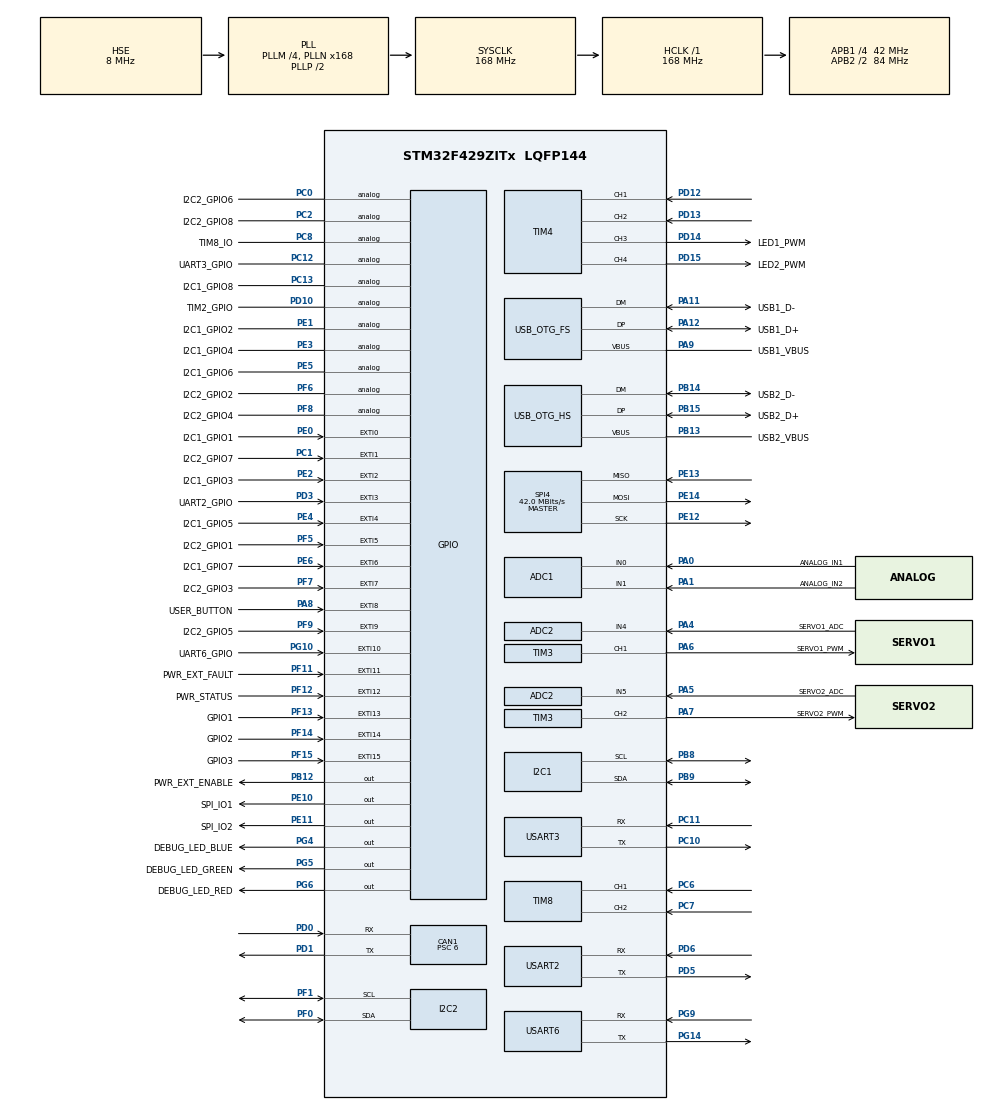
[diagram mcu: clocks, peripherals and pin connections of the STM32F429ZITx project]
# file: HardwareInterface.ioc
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ADC1.Channel-0\#ChannelRegularConversion=ADC_CHANNEL_0
ADC1.ClockPrescaler=ADC_CLOCK_SYNC_PCLK_DIV6
ADC1.NbrOfConversionFlag=1
ADC1.Rank-0\#ChannelRegularConversion=1
ADC1.SamplingTime-0\#ChannelRegularConversion=ADC_SAMPLETIME_3CYCLES
ADC1.master=1
ADC2.Channel-0\#ChannelRegularConversion=ADC_CHANNEL_4
ADC2.ClockPrescaler=ADC_CLOCK_SYNC_PCLK_DIV6
ADC2.NbrOfConversionFlag=1
ADC2.Rank-0\#ChannelRegularConversion=1
ADC2.SamplingTime-0\#ChannelRegularConversion=ADC_SAMPLETIME_3CYCLES
CAN1.BS1=CAN_BS1_11TQ
CAN1.BS2=CAN_BS2_2TQ
CAN1.CalculateBaudRate=500000
CAN1.CalculateTimeBit=2000
CAN1.CalculateTimeQuantum=142.85714285714286
CAN1.NART=ENABLE
CAN1.Prescaler=6
CAN1.SJW=CAN_SJW_4TQ
Dma.ADC1.8.Direction=DMA_PERIPH_TO_MEMORY
Dma.ADC1.8.FIFOMode=DMA_FIFOMODE_DISABLE
Dma.ADC1.8.Instance=DMA2_Stream0
Dma.ADC1.8.MemDataAlignment=DMA_MDATAALIGN_HALFWORD
Dma.ADC1.8.MemInc=DMA_MINC_ENABLE
Dma.ADC1.8.Mode=DMA_NORMAL
Dma.ADC1.8.PeriphDataAlignment=DMA_PDATAALIGN_HALFWORD
Dma.ADC1.8.PeriphInc=DMA_PINC_DISABLE
Dma.ADC1.8.Priority=DMA_PRIORITY_LOW
Dma.ADC2.7.Direction=DMA_PERIPH_TO_MEMORY
Dma.ADC2.7.FIFOMode=DMA_FIFOMODE_DISABLE
Dma.ADC2.7.Instance=DMA2_Stream2
Dma.ADC2.7.MemDataAlignment=DMA_MDATAALIGN_HALFWORD
Dma.ADC2.7.MemInc=DMA_MINC_ENABLE
Dma.ADC2.7.Mode=DMA_NORMAL
Dma.ADC2.7.PeriphDataAlignment=DMA_PDATAALIGN_HALFWORD
Dma.ADC2.7.PeriphInc=DMA_PINC_DISABLE
Dma.ADC2.7.Priority=DMA_PRIORITY_LOW
Dma.MEMTOMEM.9.Direction=DMA_MEMORY_TO_MEMORY
Dma.MEMTOMEM.9.FIFOMode=DMA_FIFOMODE_ENABLE
Dma.MEMTOMEM.9.FIFOThreshold=DMA_FIFO_THRESHOLD_FULL
Dma.MEMTOMEM.9.Instance=DMA2_Stream3
Dma.MEMTOMEM.9.MemBurst=DMA_MBURST_SINGLE
Dma.MEMTOMEM.9.MemDataAlignment=DMA_MDATAALIGN_BYTE
Dma.MEMTOMEM.9.MemInc=DMA_MINC_ENABLE
Dma.MEMTOMEM.9.Mode=DMA_NORMAL
Dma.MEMTOMEM.9.PeriphBurst=DMA_PBURST_SINGLE
Dma.MEMTOMEM.9.PeriphDataAlignment=DMA_PDATAALIGN_BYTE
Dma.MEMTOMEM.9.PeriphInc=DMA_PINC_ENABLE
Dma.MEMTOMEM.9.Priority=DMA_PRIORITY_LOW
Dma.Request0=USART2_RX
Dma.Request1=USART2_TX
Dma.Request2=USART3_RX
Dma.Request3=USART3_TX
Dma.Request4=USART6_RX
Dma.Request5=USART6_TX
Dma.Request6=TIM4_CH3
Dma.Request7=ADC2
Dma.Request8=ADC1
Dma.Request9=MEMTOMEM
Dma.TIM4_CH3.6.Direction=DMA_MEMORY_TO_PERIPH
Dma.TIM4_CH3.6.FIFOMode=DMA_FIFOMODE_DISABLE
Dma.TIM4_CH3.6.Instance=DMA1_Stream7
Dma.TIM4_CH3.6.MemDataAlignment=DMA_MDATAALIGN_HALFWORD
Dma.TIM4_CH3.6.MemInc=DMA_MINC_ENABLE
Dma.TIM4_CH3.6.Mode=DMA_NORMAL
Dma.TIM4_CH3.6.PeriphDataAlignment=DMA_PDATAALIGN_HALFWORD
Dma.TIM4_CH3.6.PeriphInc=DMA_PINC_DISABLE
Dma.TIM4_CH3.6.Priority=DMA_PRIORITY_LOW
Dma.USART2_RX.0.Direction=DMA_PERIPH_TO_MEMORY
Dma.USART2_RX.0.FIFOMode=DMA_FIFOMODE_DISABLE
Dma.USART2_RX.0.Instance=DMA1_Stream5
Dma.USART2_RX.0.MemDataAlignment=DMA_MDATAALIGN_BYTE
Dma.USART2_RX.0.MemInc=DMA_MINC_ENABLE
Dma.USART2_RX.0.Mode=DMA_NORMAL
Dma.USART2_RX.0.PeriphDataAlignment=DMA_PDATAALIGN_BYTE
Dma.USART2_RX.0.PeriphInc=DMA_PINC_DISABLE
Dma.USART2_RX.0.Priority=DMA_PRIORITY_LOW
Dma.USART2_TX.1.Direction=DMA_MEMORY_TO_PERIPH
Dma.USART2_TX.1.FIFOMode=DMA_FIFOMODE_DISABLE
Dma.USART2_TX.1.Instance=DMA1_Stream6
Dma.USART2_TX.1.MemDataAlignment=DMA_MDATAALIGN_BYTE
Dma.USART2_TX.1.MemInc=DMA_MINC_ENABLE
Dma.USART2_TX.1.Mode=DMA_NORMAL
Dma.USART2_TX.1.PeriphDataAlignment=DMA_PDATAALIGN_BYTE
Dma.USART2_TX.1.PeriphInc=DMA_PINC_DISABLE
Dma.USART2_TX.1.Priority=DMA_PRIORITY_LOW
Dma.USART3_RX.2.Direction=DMA_PERIPH_TO_MEMORY
Dma.USART3_RX.2.FIFOMode=DMA_FIFOMODE_DISABLE
Dma.USART3_RX.2.Instance=DMA1_Stream1
Dma.USART3_RX.2.MemDataAlignment=DMA_MDATAALIGN_BYTE
Dma.USART3_RX.2.MemInc=DMA_MINC_ENABLE
Dma.USART3_RX.2.Mode=DMA_NORMAL
Dma.USART3_RX.2.PeriphDataAlignment=DMA_PDATAALIGN_BYTE
Dma.USART3_RX.2.PeriphInc=DMA_PINC_DISABLE
Dma.USART3_RX.2.Priority=DMA_PRIORITY_LOW
Dma.USART3_TX.3.Direction=DMA_MEMORY_TO_PERIPH
Dma.USART3_TX.3.FIFOMode=DMA_FIFOMODE_DISABLE
Dma.USART3_TX.3.Instance=DMA1_Stream3
Dma.USART3_TX.3.MemDataAlignment=DMA_MDATAALIGN_BYTE
Dma.USART3_TX.3.MemInc=DMA_MINC_ENABLE
Dma.USART3_TX.3.Mode=DMA_NORMAL
Dma.USART3_TX.3.PeriphDataAlignment=DMA_PDATAALIGN_BYTE
Dma.USART3_TX.3.PeriphInc=DMA_PINC_DISABLE
Dma.USART3_TX.3.Priority=DMA_PRIORITY_LOW
Dma.USART6_RX.4.Direction=DMA_PERIPH_TO_MEMORY
Dma.USART6_RX.4.FIFOMode=DMA_FIFOMODE_DISABLE
Dma.USART6_RX.4.Instance=DMA2_Stream1
Dma.USART6_RX.4.MemDataAlignment=DMA_MDATAALIGN_BYTE
Dma.USART6_RX.4.MemInc=DMA_MINC_ENABLE
Dma.USART6_RX.4.Mode=DMA_NORMAL
Dma.USART6_RX.4.PeriphDataAlignment=DMA_PDATAALIGN_BYTE
Dma.USART6_RX.4.PeriphInc=DMA_PINC_DISABLE
Dma.USART6_RX.4.Priority=DMA_PRIORITY_LOW
Dma.USART6_TX.5.Direction=DMA_MEMORY_TO_PERIPH
Dma.USART6_TX.5.FIFOMode=DMA_FIFOMODE_DISABLE
Dma.USART6_TX.5.Instance=DMA2_Stream6
Dma.USART6_TX.5.MemDataAlignment=DMA_MDATAALIGN_BYTE
Dma.USART6_TX.5.MemInc=DMA_MINC_ENABLE
Dma.USART6_TX.5.Mode=DMA_NORMAL
Dma.USART6_TX.5.PeriphDataAlignment=DMA_PDATAALIGN_BYTE
Dma.USART6_TX.5.PeriphInc=DMA_PINC_DISABLE
Dma.USART6_TX.5.Priority=DMA_PRIORITY_LOW
FREERTOS.INCLUDE_pcTaskGetTaskName=1
FREERTOS.Tasks01=mainTask,24,4096,StartMainTask,Default,NULL,Static,mainTaskBuffer,mainTaskControlBlock
FREERTOS.configCHECK_FOR_STACK_OVERFLOW=2
FREERTOS.configENABLE_BACKWARD_COMPATIBILITY=1
FREERTOS.configENABLE_FPU=1
FREERTOS.configGENERATE_RUN_TIME_STATS=1
FREERTOS.configMAX_TASK_NAME_LEN=32
FREERTOS.configRECORD_STACK_HIGH_ADDRESS=1
FREERTOS.configTOTAL_HEAP_SIZE=16384
FREERTOS.configUSE_MALLOC_FAILED_HOOK=1
FREERTOS.configUSE_STATS_FORMATTING_FUNCTIONS=1
FREERTOS.copyHeapFile=0
Mcu.Family=STM32F4
Mcu.Name=STM32F429ZITx
Mcu.Package=LQFP144
NVIC.CAN1_RX0_IRQn=true\:5\:0\:false\:false\:true\:true\:true\:true\:true
NVIC.CAN1_RX1_IRQn=true\:5\:0\:false\:false\:true\:true\:true\:true\:true
NVIC.CAN1_SCE_IRQn=true\:5\:0\:false\:false\:true\:true\:true\:true\:true
NVIC.CAN1_TX_IRQn=true\:5\:0\:false\:false\:true\:true\:true\:true\:true
NVIC.DMA1_Stream1_IRQn=true\:5\:0\:false\:false\:true\:true\:false\:true\:true
NVIC.DMA1_Stream3_IRQn=true\:5\:0\:false\:false\:true\:true\:false\:true\:true
NVIC.DMA1_Stream5_IRQn=true\:5\:0\:false\:false\:true\:true\:false\:true\:true
NVIC.DMA1_Stream6_IRQn=true\:5\:0\:false\:false\:true\:true\:false\:true\:true
NVIC.DMA1_Stream7_IRQn=true\:5\:0\:false\:false\:true\:true\:false\:true\:true
NVIC.DMA2_Stream0_IRQn=true\:5\:0\:false\:false\:true\:true\:false\:true\:true
NVIC.DMA2_Stream1_IRQn=true\:5\:0\:false\:false\:true\:true\:false\:true\:true
NVIC.DMA2_Stream2_IRQn=true\:5\:0\:false\:false\:true\:true\:false\:true\:true
NVIC.DMA2_Stream3_IRQn=true\:5\:0\:false\:false\:true\:true\:true\:true\:true
NVIC.DMA2_Stream6_IRQn=true\:5\:0\:false\:false\:true\:true\:false\:true\:true
NVIC.EXTI0_IRQn=true\:5\:0\:false\:false\:true\:true\:true\:true\:true
NVIC.EXTI15_10_IRQn=true\:5\:0\:false\:false\:true\:true\:true\:true\:true
NVIC.EXTI1_IRQn=true\:5\:0\:false\:false\:true\:true\:true\:true\:true
NVIC.EXTI2_IRQn=true\:5\:0\:false\:false\:true\:true\:true\:true\:true
NVIC.EXTI3_IRQn=true\:5\:0\:false\:false\:true\:true\:true\:true\:true
NVIC.EXTI4_IRQn=true\:5\:0\:false\:false\:true\:true\:true\:true\:true
NVIC.EXTI9_5_IRQn=true\:5\:0\:false\:false\:true\:true\:true\:true\:true
NVIC.I2C1_ER_IRQn=true\:5\:0\:false\:false\:true\:true\:true\:true\:true
NVIC.I2C1_EV_IRQn=true\:5\:0\:false\:false\:true\:true\:true\:true\:true
NVIC.I2C2_ER_IRQn=true\:5\:0\:false\:false\:true\:true\:true\:true\:true
NVIC.I2C2_EV_IRQn=true\:5\:0\:false\:false\:true\:true\:true\:true\:true
NVIC.OTG_FS_IRQn=true\:5\:0\:false\:false\:true\:true\:false\:true\:true
NVIC.OTG_HS_EP1_IN_IRQn=true\:5\:0\:false\:false\:true\:true\:false\:true\:true
NVIC.OTG_HS_EP1_OUT_IRQn=true\:5\:0\:false\:false\:true\:true\:false\:true\:true
NVIC.OTG_HS_IRQn=true\:5\:0\:false\:false\:true\:true\:false\:true\:true
NVIC.PriorityGroup=NVIC_PRIORITYGROUP_4
NVIC.TIM7_IRQn=true\:15\:0\:false\:false\:true\:false\:false\:true\:true
NVIC.TIM8_TRG_COM_TIM14_IRQn=true\:5\:0\:false\:false\:true\:false\:false\:true\:true
NVIC.TimeBase=TIM7_IRQn
NVIC.TimeBaseIP=TIM7
NVIC.USART2_IRQn=true\:5\:0\:false\:false\:true\:true\:true\:true\:true
NVIC.USART3_IRQn=true\:5\:0\:false\:false\:true\:true\:true\:true\:true
NVIC.USART6_IRQn=true\:5\:0\:false\:false\:true\:true\:true\:true\:true
PA0/WKUP.GPIO_Label=ANALOG_IN1
PA0/WKUP.Signal=ADCx_IN0
PA1.GPIO_Label=ANALOG_IN2
PA1.Signal=ADCx_IN1
PA11.GPIO_Label=USB1_D-
PA11.Mode=Device_Only
PA11.Signal=USB_OTG_FS_DM
PA12.GPIO_Label=USB1_D+
PA12.Mode=Device_Only
PA12.Signal=USB_OTG_FS_DP
PA13.GPIO_Label=SWD_SWDIO
PA13.Mode=Trace_Asynchronous_SW
PA13.Signal=SYS_JTMS-SWDIO
PA14.GPIO_Label=SWD_SWCLK
PA14.Mode=Trace_Asynchronous_SW
PA14.Signal=SYS_JTCK-SWCLK
PA4.GPIO_Label=SERVO1_ADC
PA4.Signal=ADCx_IN4
PA5.GPIO_Label=SERVO2_ADC
PA5.Signal=ADCx_IN5
PA6.GPIO_Label=SERVO1_PWM
PA6.Signal=S_TIM3_CH1
PA7.GPIO_Label=SERVO2_PWM
PA7.Signal=S_TIM3_CH2
PA8.GPIO_Label=USER_BUTTON
PA8.GPIO_ModeDefaultEXTI=GPIO_MODE_IT_RISING_FALLING
PA8.Signal=GPXTI8
PA9.GPIO_Label=USB1_VBUS
PA9.Mode=Activate_VBUS
PA9.Signal=USB_OTG_FS_VBUS
PB12.GPIO_Label=PWR_EXT_ENABLE
PB12.Signal=GPIO_Output
PB13.GPIO_Label=USB2_VBUS
PB13.Mode=Activate_VBUS_FS
PB13.Signal=USB_OTG_HS_VBUS
PB14.GPIO_Label=USB2_D-
PB14.Mode=Device_Only_FS
PB14.Signal=USB_OTG_HS_DM
PB15.GPIO_Label=USB2_D+
PB15.Mode=Device_Only_FS
PB15.Signal=USB_OTG_HS_DP
PB3.GPIO_Label=SWD_SWO
PB3.Mode=Trace_Asynchronous_SW
PB3.Signal=SYS_JTDO-SWO
PB8.Mode=I2C
PB8.Signal=I2C1_SCL
PB9.Mode=I2C
PB9.Signal=I2C1_SDA
PC0.GPIO_Label=I2C2_GPIO6
PC0.Signal=GPIO_Analog
PC1.GPIO_Label=I2C2_GPIO7
PC1.Signal=GPXTI1
PC10.Mode=Asynchronous
PC10.Signal=USART3_TX
PC11.Mode=Asynchronous
PC11.Signal=USART3_RX
PC12.GPIO_Label=UART3_GPIO
PC12.Signal=GPIO_Analog
PC13.GPIO_Label=I2C1_GPIO8
PC13.Signal=GPIO_Analog
PC2.GPIO_Label=I2C2_GPIO8
PC2.Signal=GPIO_Analog
PC6.Signal=S_TIM8_CH1
PC7.Signal=S_TIM8_CH2
PC8.GPIO_Label=TIM8_IO
PC8.Signal=GPIO_Analog
PD0.Mode=CAN_Activate
PD0.Signal=CAN1_RX
PD1.Mode=CAN_Activate
PD1.Signal=CAN1_TX
PD10.GPIO_Label=TIM2_GPIO
PD10.Signal=GPIO_Analog
PD12.Signal=S_TIM4_CH1
PD13.Signal=S_TIM4_CH2
PD14.GPIO_Label=LED1_PWM
PD14.Signal=S_TIM4_CH3
PD15.GPIO_Label=LED2_PWM
PD15.Signal=S_TIM4_CH4
PD3.GPIO_Label=UART2_GPIO
PD3.Signal=GPXTI3
PD5.Mode=Asynchronous
PD5.Signal=USART2_TX
PD6.Mode=Asynchronous
PD6.Signal=USART2_RX
PE0.GPIO_Label=I2C1_GPIO1
PE0.Signal=GPXTI0
PE1.GPIO_Label=I2C1_GPIO2
PE1.Signal=GPIO_Analog
PE10.GPIO_Label=SPI_IO1
PE10.Signal=GPIO_Output
PE11.GPIO_Label=SPI_IO2
PE11.Signal=GPIO_Output
PE12.Mode=Full_Duplex_Master
PE12.Signal=SPI4_SCK
PE13.Mode=Full_Duplex_Master
PE13.Signal=SPI4_MISO
PE14.Mode=Full_Duplex_Master
PE14.Signal=SPI4_MOSI
PE2.GPIO_Label=I2C1_GPIO3
PE2.Signal=GPXTI2
PE3.GPIO_Label=I2C1_GPIO4
PE3.Signal=GPIO_Analog
PE4.GPIO_Label=I2C1_GPIO5
PE4.Signal=GPXTI4
PE5.GPIO_Label=I2C1_GPIO6
PE5.GPIO_Mode=GPIO_MODE_ANALOG
PE5.Signal=GPIO_Analog
PE6.GPIO_Label=I2C1_GPIO7
PE6.Signal=GPXTI6
PF0.Mode=I2C
PF0.Signal=I2C2_SDA
PF1.Mode=I2C
PF1.Signal=I2C2_SCL
PF11.GPIO_Label=PWR_EXT_FAULT
PF11.Signal=GPXTI11
PF12.GPIO_Label=PWR_STATUS
PF12.Signal=GPXTI12
PF13.GPIO_Label=GPIO1
PF13.Signal=GPXTI13
PF14.GPIO_Label=GPIO2
PF14.Signal=GPXTI14
PF15.GPIO_Label=GPIO3
PF15.Signal=GPXTI15
PF5.GPIO_Label=I2C2_GPIO1
PF5.Signal=GPXTI5
PF6.GPIO_Label=I2C2_GPIO2
PF6.Signal=GPIO_Analog
PF7.GPIO_Label=I2C2_GPIO3
PF7.Signal=GPXTI7
PF8.GPIO_Label=I2C2_GPIO4
PF8.Signal=GPIO_Analog
PF9.GPIO_Label=I2C2_GPIO5
PF9.Signal=GPXTI9
PG10.GPIO_Label=UART6_GPIO
PG10.Signal=GPXTI10
PG14.Mode=Asynchronous
PG14.Signal=USART6_TX
PG4.GPIO_Label=DEBUG_LED_BLUE
PG4.Signal=GPIO_Output
PG5.GPIO_Label=DEBUG_LED_GREEN
PG5.Signal=GPIO_Output
PG6.GPIO_Label=DEBUG_LED_RED
PG6.Signal=GPIO_Output
PG9.Mode=Asynchronous
PG9.Signal=USART6_RX
PH0/OSC_IN.Mode=HSE-External-Clock-Source
PH0/OSC_IN.Signal=RCC_OSC_IN
PH1/OSC_OUT.Mode=HSE-External-Clock-Source
PH1/OSC_OUT.Signal=RCC_OSC_OUT
ProjectManager.HeapSize=0x200
ProjectManager.StackSize=0x400
ProjectManager.TargetToolchain=CMake
RCC.48MHZClocksFreq_Value=48000000
RCC.AHBFreq_Value=168000000
RCC.APB1CLKDivider=RCC_HCLK_DIV4
RCC.APB1Freq_Value=42000000
RCC.APB1TimFreq_Value=84000000
RCC.APB2CLKDivider=RCC_HCLK_DIV2
RCC.APB2Freq_Value=84000000
RCC.APB2TimFreq_Value=168000000
RCC.CortexFreq_Value=168000000
RCC.HCLKFreq_Value=168000000
RCC.HSE_VALUE=8000000
RCC.HSI_VALUE=16000000
RCC.LSE_VALUE=32768
RCC.PLLM=4
RCC.PLLN=168
RCC.PLLQ=7
RCC.SYSCLKFreq_VALUE=168000000
RCC.SYSCLKSource=RCC_SYSCLKSOURCE_PLLCLK
RCC.VCOOutputFreq_Value=336000000
SH.ADCx_IN0.0=ADC1_IN0,IN0
SH.ADCx_IN1.0=ADC1_IN1,IN1
SH.ADCx_IN4.0=ADC2_IN4,IN4
SH.ADCx_IN5.0=ADC2_IN5,IN5
SH.S_TIM3_CH1.0=TIM3_CH1,PWM Generation1 CH1
SH.S_TIM3_CH2.0=TIM3_CH2,PWM Generation2 CH2
SH.S_TIM4_CH1.0=TIM4_CH1,Input_Capture1_from_TI1
SH.S_TIM4_CH2.0=TIM4_CH2,Input_Capture2_from_TI2
SH.S_TIM4_CH3.0=TIM4_CH3,PWM Generation3 CH3
SH.S_TIM4_CH4.0=TIM4_CH4,PWM Generation4 CH4
SH.S_TIM8_CH1.0=TIM8_CH1,Input_Capture1_from_TI1
SH.S_TIM8_CH2.0=TIM8_CH2,Input_Capture2_from_TI2
SPI4.BaudRatePrescaler=SPI_BAUDRATEPRESCALER_2
SPI4.CalculateBaudRate=42.0 MBits/s
SPI4.Direction=SPI_DIRECTION_2LINES
SPI4.Mode=SPI_MODE_MASTER
SPI4.VirtualType=VM_MASTER
TIM3.Channel-PWM\ Generation1\ CH1=TIM_CHANNEL_1
TIM3.Channel-PWM\ Generation2\ CH2=TIM_CHANNEL_2
TIM4.Channel-Input_Capture1_from_TI1=TIM_CHANNEL_1
TIM4.Channel-Input_Capture2_from_TI2=TIM_CHANNEL_2
TIM4.Channel-PWM\ Generation3\ CH3=TIM_CHANNEL_3
TIM4.Channel-PWM\ Generation4\ CH4=TIM_CHANNEL_4
TIM5.Channel-Output\ Compare1\ No\ Output=TIM_CHANNEL_1
TIM8.Channel-Input_Capture1_from_TI1=TIM_CHANNEL_1
TIM8.Channel-Input_Capture2_from_TI2=TIM_CHANNEL_2
USART2.VirtualMode=VM_ASYNC
USART3.VirtualMode=VM_ASYNC
USART6.VirtualMode=VM_ASYNC
USB_DEVICE.CLASS_NAME_FS=CDC
USB_DEVICE.CLASS_NAME_HS=CDC
USB_DEVICE.MANUFACTURER_STRING-CDC_HS=CAuDri e.V.
USB_DEVICE.PID_CDC_FS=22338
USB_DEVICE.PID_CDC_HS=22334
USB_DEVICE.PRODUCT_STRING_CDC_FS=Hardware Interface Host Port
USB_DEVICE.PRODUCT_STRING_CDC_HS=Hardware Interface Debug Port
USB_DEVICE.VirtualMode-CDC_FS=Cdc
USB_DEVICE.VirtualMode-CDC_HS=Cdc
USB_DEVICE.VirtualModeFS=Cdc_FS
USB_DEVICE.VirtualModeHS=Cdc_HS
USB_OTG_FS.Sof_enable=DISABLE
USB_OTG_FS.VirtualMode=Device_Only
USB_OTG_HS.VirtualMode-Device_Only_FS=Device_Only_FS
USB_OTG_HS.use_dedicated_ep1-Device_Only_FS=DISABLE
VP_FREERTOS_VS_CMSIS_V2.Mode=CMSIS_V2
VP_SYS_VS_tim7.Mode=TIM7
VP_TIM5_VS_no_output1.Mode=Output Compare1 No Output
VP_USB_DEVICE_VS_USB_DEVICE_CDC_FS.Mode=CDC_FS
VP_USB_DEVICE_VS_USB_DEVICE_CDC_HS.Mode=CDC_HS
board=custom

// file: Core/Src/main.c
/* USER CODE BEGIN Header */
/**
  ******************************************************************************
  * @file           : main.c
  * @brief          : Main program body
  ******************************************************************************
  * @attention
  *
  * Copyright (c) 2025 STMicroelectronics.
  * All rights reserved.
  *
  * This software is licensed under terms that can be found in the LICENSE file
  * in the root directory of this software component.
  * If no LICENSE file comes with this software, it is provided AS-IS.
  *
  ******************************************************************************
  */
/* USER CODE END Header */
#include "main.h"
#include "cmsis_os.h"
#include "usb_device.h"

/* USER CODE BEGIN Includes */

#include "logger.h"
#include "thread_safe_can.h"
#include "thread_safe_i2c.h"
#include "thread_safe_adc.h"
#include "usb_device_helper.h"
#include "usbd_desc.h"

/* USER CODE END Includes */

typedef StaticTask_t osStaticThreadDef_t;

ADC_HandleTypeDef hadc1;
ADC_HandleTypeDef hadc2;
DMA_HandleTypeDef hdma_adc1;
DMA_HandleTypeDef hdma_adc2;

CAN_HandleTypeDef hcan1;

I2C_HandleTypeDef hi2c1;
I2C_HandleTypeDef hi2c2;

SPI_HandleTypeDef hspi4;

TIM_HandleTypeDef htim3;
TIM_HandleTypeDef htim4;
TIM_HandleTypeDef htim5;
TIM_HandleTypeDef htim8;
DMA_HandleTypeDef hdma_tim4_ch3;

UART_HandleTypeDef huart2;
UART_HandleTypeDef huart3;
UART_HandleTypeDef huart6;
DMA_HandleTypeDef hdma_usart2_rx;
DMA_HandleTypeDef hdma_usart2_tx;
DMA_HandleTypeDef hdma_usart3_rx;
DMA_HandleTypeDef hdma_usart3_tx;
DMA_HandleTypeDef hdma_usart6_rx;
DMA_HandleTypeDef hdma_usart6_tx;

DMA_HandleTypeDef hdma_memtomem_dma2_stream3;
/* Definitions for mainTask */
osThreadId_t mainTaskHandle;
uint32_t mainTaskBuffer[ 4096 ];
osStaticThreadDef_t mainTaskControlBlock;
const osThreadAttr_t mainTask_attributes = {
  .name = "mainTask",
  .cb_mem = &mainTaskControlBlock,
  .cb_size = sizeof(mainTaskControlBlock),
  .stack_mem = &mainTaskBuffer[0],
  .stack_size = sizeof(mainTaskBuffer),
  .priority = (osPriority_t) osPriorityNormal,
};

void SystemClock_Config(void);
static void MX_GPIO_Init(void);
static void MX_DMA_Init(void);
static void MX_ADC1_Init(void);
static void MX_CAN1_Init(void);
static void MX_I2C1_Init(void);
static void MX_I2C2_Init(void);
static void MX_SPI4_Init(void);
static void MX_USART2_UART_Init(void);
static void MX_USART3_UART_Init(void);
static void MX_ADC2_Init(void);
static void MX_TIM3_Init(void);
static void MX_USART6_UART_Init(void);
static void MX_TIM4_Init(void);
static void MX_TIM8_Init(void);
static void MX_TIM5_Init(void);
void StartMainTask(void *argument);

/* USER CODE BEGIN PFP */

// CAuDri - Main entry point in main.cpp
extern void mainTask();

/* USER CODE END PFP */

int main(void)
{

  /* USER CODE BEGIN 1 */

  // CAuDri - Some debug reset paths leave BASEPRI raised, which masks the HAL tick.
  __set_BASEPRI(0U);

  /* USER CODE END 1 */

  /* MCU Configuration--------------------------------------------------------*/

  /* Reset of all peripherals, Initializes the Flash interface and the Systick. */
  HAL_Init();

  /* Configure the system clock */
  SystemClock_Config();

  /* USER CODE BEGIN SysInit */

  // CAuDri - Initialize the trace recorder for debugging with Tracealyzer
  #ifdef DEBUG_USE_TRACE_RECORDER
    xTraceInitialize();
  #endif

  /* USER CODE END SysInit */

  /* Initialize all configured peripherals */
  MX_GPIO_Init();
  MX_DMA_Init();
  MX_ADC1_Init();
  MX_CAN1_Init();
  MX_I2C1_Init();
  MX_I2C2_Init();
  MX_SPI4_Init();
  MX_USART2_UART_Init();
  MX_USART3_UART_Init();
  MX_ADC2_Init();
  MX_TIM3_Init();
  MX_USART6_UART_Init();
  MX_TIM4_Init();
  MX_TIM8_Init();
  MX_TIM5_Init();
  /* USER CODE BEGIN 2 */

  // CAuDri - Replace CubeMX's occasionally broken generated USB serial callback
  usb_serial_descriptor_install(&FS_Desc, &HS_Desc);

  /* USER CODE END 2 */

  /* Init scheduler */
  osKernelInitialize();

  /* Create the thread(s) */
  /* creation of mainTask */
  mainTaskHandle = osThreadNew(StartMainTask, NULL, &mainTask_attributes);

  /* USER CODE BEGIN RTOS_THREADS */

  // CAuDri - Initialize the logging interface and start the logger thread
  if (!logger_init()) {
      LogInline("Main: Failed to initialize logger");
  } else {
      LogClear();
  }

  /* add threads, ... */
  /* USER CODE END RTOS_THREADS */

  /* Start scheduler */
  osKernelStart();

  /* We should never get here as control is now taken by the scheduler */

  /* Infinite loop */
  while (1)
  {

  }
}

void SystemClock_Config(void)
{
  RCC_OscInitTypeDef RCC_OscInitStruct = {0};
  RCC_ClkInitTypeDef RCC_ClkInitStruct = {0};

  /** Configure the main internal regulator output voltage
  */
  __HAL_RCC_PWR_CLK_ENABLE();
  __HAL_PWR_VOLTAGESCALING_CONFIG(PWR_REGULATOR_VOLTAGE_SCALE1);

  /** Initializes the RCC Oscillators according to the specified parameters
  * in the RCC_OscInitTypeDef structure.
  */
  RCC_OscInitStruct.OscillatorType = RCC_OSCILLATORTYPE_HSE;
  RCC_OscInitStruct.HSEState = RCC_HSE_BYPASS;
  RCC_OscInitStruct.PLL.PLLState = RCC_PLL_ON;
  RCC_OscInitStruct.PLL.PLLSource = RCC_PLLSOURCE_HSE;
  RCC_OscInitStruct.PLL.PLLM = 4;
  RCC_OscInitStruct.PLL.PLLN = 168;
  RCC_OscInitStruct.PLL.PLLP = RCC_PLLP_DIV2;
  RCC_OscInitStruct.PLL.PLLQ = 7;
  if (HAL_RCC_OscConfig(&RCC_OscInitStruct) != HAL_OK)
  {
    Error_Handler();
  }

  /** Initializes the CPU, AHB and APB buses clocks
  */
  RCC_ClkInitStruct.ClockType = RCC_CLOCKTYPE_HCLK|RCC_CLOCKTYPE_SYSCLK
                              |RCC_CLOCKTYPE_PCLK1|RCC_CLOCKTYPE_PCLK2;
  RCC_ClkInitStruct.SYSCLKSource = RCC_SYSCLKSOURCE_PLLCLK;
  RCC_ClkInitStruct.AHBCLKDivider = RCC_SYSCLK_DIV1;
  RCC_ClkInitStruct.APB1CLKDivider = RCC_HCLK_DIV4;
  RCC_ClkInitStruct.APB2CLKDivider = RCC_HCLK_DIV2;

  if (HAL_RCC_ClockConfig(&RCC_ClkInitStruct, FLASH_LATENCY_5) != HAL_OK)
  {
    Error_Handler();
  }
}

static void MX_ADC1_Init(void)
{

  ADC_ChannelConfTypeDef sConfig = {0};

  /** Configure the global features of the ADC (Clock, Resolution, Data Alignment and number of conversion)
  */
  hadc1.Instance = ADC1;
  hadc1.Init.ClockPrescaler = ADC_CLOCK_SYNC_PCLK_DIV6;
  hadc1.Init.Resolution = ADC_RESOLUTION_12B;
  hadc1.Init.ScanConvMode = DISABLE;
  hadc1.Init.ContinuousConvMode = DISABLE;
  hadc1.Init.DiscontinuousConvMode = DISABLE;
  hadc1.Init.ExternalTrigConvEdge = ADC_EXTERNALTRIGCONVEDGE_NONE;
  hadc1.Init.ExternalTrigConv = ADC_SOFTWARE_START;
  hadc1.Init.DataAlign = ADC_DATAALIGN_RIGHT;
  hadc1.Init.NbrOfConversion = 1;
  hadc1.Init.DMAContinuousRequests = DISABLE;
  hadc1.Init.EOCSelection = ADC_EOC_SINGLE_CONV;
  if (HAL_ADC_Init(&hadc1) != HAL_OK)
  {
    Error_Handler();
  }

  /** Configure for the selected ADC regular channel its corresponding rank in the sequencer and its sample time.
  */
  sConfig.Channel = ADC_CHANNEL_0;
  sConfig.Rank = 1;
  sConfig.SamplingTime = ADC_SAMPLETIME_3CYCLES;
  if (HAL_ADC_ConfigChannel(&hadc1, &sConfig) != HAL_OK)
  {
    Error_Handler();
  }

}

static void MX_ADC2_Init(void)
{

  ADC_ChannelConfTypeDef sConfig = {0};

  /** Configure the global features of the ADC (Clock, Resolution, Data Alignment and number of conversion)
  */
  hadc2.Instance = ADC2;
  hadc2.Init.ClockPrescaler = ADC_CLOCK_SYNC_PCLK_DIV6;
  hadc2.Init.Resolution = ADC_RESOLUTION_12B;
  hadc2.Init.ScanConvMode = DISABLE;
  hadc2.Init.ContinuousConvMode = DISABLE;
  hadc2.Init.DiscontinuousConvMode = DISABLE;
  hadc2.Init.ExternalTrigConvEdge = ADC_EXTERNALTRIGCONVEDGE_NONE;
  hadc2.Init.ExternalTrigConv = ADC_SOFTWARE_START;
  hadc2.Init.DataAlign = ADC_DATAALIGN_RIGHT;
  hadc2.Init.NbrOfConversion = 1;
  hadc2.Init.DMAContinuousRequests = DISABLE;
  hadc2.Init.EOCSelection = ADC_EOC_SINGLE_CONV;
  if (HAL_ADC_Init(&hadc2) != HAL_OK)
  {
    Error_Handler();
  }

  /** Configure for the selected ADC regular channel its corresponding rank in the sequencer and its sample time.
  */
  sConfig.Channel = ADC_CHANNEL_4;
  sConfig.Rank = 1;
  sConfig.SamplingTime = ADC_SAMPLETIME_3CYCLES;
  if (HAL_ADC_ConfigChannel(&hadc2, &sConfig) != HAL_OK)
  {
    Error_Handler();
  }

}

static void MX_CAN1_Init(void)
{

  hcan1.Instance = CAN1;
  hcan1.Init.Prescaler = 6;
  hcan1.Init.Mode = CAN_MODE_NORMAL;
  hcan1.Init.SyncJumpWidth = CAN_SJW_4TQ;
  hcan1.Init.TimeSeg1 = CAN_BS1_11TQ;
  hcan1.Init.TimeSeg2 = CAN_BS2_2TQ;
  hcan1.Init.TimeTriggeredMode = DISABLE;
  hcan1.Init.AutoBusOff = DISABLE;
  hcan1.Init.AutoWakeUp = DISABLE;
  hcan1.Init.AutoRetransmission = ENABLE;
  hcan1.Init.ReceiveFifoLocked = DISABLE;
  hcan1.Init.TransmitFifoPriority = DISABLE;
  if (HAL_CAN_Init(&hcan1) != HAL_OK)
  {
    Error_Handler();
  }

}

static void MX_I2C1_Init(void)
{

  hi2c1.Instance = I2C1;
  hi2c1.Init.ClockSpeed = 100000;
  hi2c1.Init.DutyCycle = I2C_DUTYCYCLE_2;
  hi2c1.Init.OwnAddress1 = 0;
  hi2c1.Init.AddressingMode = I2C_ADDRESSINGMODE_7BIT;
  hi2c1.Init.DualAddressMode = I2C_DUALADDRESS_DISABLE;
  hi2c1.Init.OwnAddress2 = 0;
  hi2c1.Init.GeneralCallMode = I2C_GENERALCALL_DISABLE;
  hi2c1.Init.NoStretchMode = I2C_NOSTRETCH_DISABLE;
  if (HAL_I2C_Init(&hi2c1) != HAL_OK)
  {
    Error_Handler();
  }

  /** Configure Analogue filter
  */
  if (HAL_I2CEx_ConfigAnalogFilter(&hi2c1, I2C_ANALOGFILTER_ENABLE) != HAL_OK)
  {
    Error_Handler();
  }

  /** Configure Digital filter
  */
  if (HAL_I2CEx_ConfigDigitalFilter(&hi2c1, 0) != HAL_OK)
  {
    Error_Handler();
  }

}

static void MX_I2C2_Init(void)
{

  hi2c2.Instance = I2C2;
  hi2c2.Init.ClockSpeed = 100000;
  hi2c2.Init.DutyCycle = I2C_DUTYCYCLE_2;
  hi2c2.Init.OwnAddress1 = 0;
  hi2c2.Init.AddressingMode = I2C_ADDRESSINGMODE_7BIT;
  hi2c2.Init.DualAddressMode = I2C_DUALADDRESS_DISABLE;
  hi2c2.Init.OwnAddress2 = 0;
  hi2c2.Init.GeneralCallMode = I2C_GENERALCALL_DISABLE;
  hi2c2.Init.NoStretchMode = I2C_NOSTRETCH_DISABLE;
  if (HAL_I2C_Init(&hi2c2) != HAL_OK)
  {
    Error_Handler();
  }

  /** Configure Analogue filter
  */
  if (HAL_I2CEx_ConfigAnalogFilter(&hi2c2, I2C_ANALOGFILTER_ENABLE) != HAL_OK)
  {
    Error_Handler();
  }

  /** Configure Digital filter
  */
  if (HAL_I2CEx_ConfigDigitalFilter(&hi2c2, 0) != HAL_OK)
  {
    Error_Handler();
  }

}

static void MX_SPI4_Init(void)
{

  /* SPI4 parameter configuration*/
  hspi4.Instance = SPI4;
  hspi4.Init.Mode = SPI_MODE_MASTER;
  hspi4.Init.Direction = SPI_DIRECTION_2LINES;
  hspi4.Init.DataSize = SPI_DATASIZE_8BIT;
  hspi4.Init.CLKPolarity = SPI_POLARITY_LOW;
  hspi4.Init.CLKPhase = SPI_PHASE_1EDGE;
  hspi4.Init.NSS = SPI_NSS_SOFT;
  hspi4.Init.BaudRatePrescaler = SPI_BAUDRATEPRESCALER_2;
  hspi4.Init.FirstBit = SPI_FIRSTBIT_MSB;
  hspi4.Init.TIMode = SPI_TIMODE_DISABLE;
  hspi4.Init.CRCCalculation = SPI_CRCCALCULATION_DISABLE;
  hspi4.Init.CRCPolynomial = 10;
  if (HAL_SPI_Init(&hspi4) != HAL_OK)
  {
    Error_Handler();
  }

}

static void MX_TIM3_Init(void)
{

  TIM_MasterConfigTypeDef sMasterConfig = {0};
  TIM_OC_InitTypeDef sConfigOC = {0};

  htim3.Instance = TIM3;
  htim3.Init.Prescaler = 0;
  htim3.Init.CounterMode = TIM_COUNTERMODE_UP;
  htim3.Init.Period = 65535;
  htim3.Init.ClockDivision = TIM_CLOCKDIVISION_DIV1;
  htim3.Init.AutoReloadPreload = TIM_AUTORELOAD_PRELOAD_DISABLE;
  if (HAL_TIM_PWM_Init(&htim3) != HAL_OK)
  {
    Error_Handler();
  }
  sMasterConfig.MasterOutputTrigger = TIM_TRGO_RESET;
  sMasterConfig.MasterSlaveMode = TIM_MASTERSLAVEMODE_DISABLE;
  if (HAL_TIMEx_MasterConfigSynchronization(&htim3, &sMasterConfig) != HAL_OK)
  {
    Error_Handler();
  }
  sConfigOC.OCMode = TIM_OCMODE_PWM1;
  sConfigOC.Pulse = 0;
  sConfigOC.OCPolarity = TIM_OCPOLARITY_HIGH;
  sConfigOC.OCFastMode = TIM_OCFAST_DISABLE;
  if (HAL_TIM_PWM_ConfigChannel(&htim3, &sConfigOC, TIM_CHANNEL_1) != HAL_OK)
  {
    Error_Handler();
  }
  if (HAL_TIM_PWM_ConfigChannel(&htim3, &sConfigOC, TIM_CHANNEL_2) != HAL_OK)
  {
    Error_Handler();
  }
  HAL_TIM_MspPostInit(&htim3);

}

static void MX_TIM4_Init(void)
{

  TIM_MasterConfigTypeDef sMasterConfig = {0};
  TIM_IC_InitTypeDef sConfigIC = {0};
  TIM_OC_InitTypeDef sConfigOC = {0};

  htim4.Instance = TIM4;
  htim4.Init.Prescaler = 0;
  htim4.Init.CounterMode = TIM_COUNTERMODE_UP;
  htim4.Init.Period = 65535;
  htim4.Init.ClockDivision = TIM_CLOCKDIVISION_DIV1;
  htim4.Init.AutoReloadPreload = TIM_AUTORELOAD_PRELOAD_DISABLE;
  if (HAL_TIM_IC_Init(&htim4) != HAL_OK)
  {
    Error_Handler();
  }
  if (HAL_TIM_PWM_Init(&htim4) != HAL_OK)
  {
    Error_Handler();
  }
  sMasterConfig.MasterOutputTrigger = TIM_TRGO_RESET;
  sMasterConfig.MasterSlaveMode = TIM_MASTERSLAVEMODE_DISABLE;
  if (HAL_TIMEx_MasterConfigSynchronization(&htim4, &sMasterConfig) != HAL_OK)
  {
    Error_Handler();
  }
  sConfigIC.ICPolarity = TIM_INPUTCHANNELPOLARITY_RISING;
  sConfigIC.ICSelection = TIM_ICSELECTION_DIRECTTI;
  sConfigIC.ICPrescaler = TIM_ICPSC_DIV1;
  sConfigIC.ICFilter = 0;
  if (HAL_TIM_IC_ConfigChannel(&htim4, &sConfigIC, TIM_CHANNEL_1) != HAL_OK)
  {
    Error_Handler();
  }
  if (HAL_TIM_IC_ConfigChannel(&htim4, &sConfigIC, TIM_CHANNEL_2) != HAL_OK)
  {
    Error_Handler();
  }
  sConfigOC.OCMode = TIM_OCMODE_PWM1;
  sConfigOC.Pulse = 0;
  sConfigOC.OCPolarity = TIM_OCPOLARITY_HIGH;
  sConfigOC.OCFastMode = TIM_OCFAST_DISABLE;
  if (HAL_TIM_PWM_ConfigChannel(&htim4, &sConfigOC, TIM_CHANNEL_3) != HAL_OK)
  {
    Error_Handler();
  }
  if (HAL_TIM_PWM_ConfigChannel(&htim4, &sConfigOC, TIM_CHANNEL_4) != HAL_OK)
  {
    Error_Handler();
  }
  HAL_TIM_MspPostInit(&htim4);

}

static void MX_TIM5_Init(void)
{

  TIM_MasterConfigTypeDef sMasterConfig = {0};
  TIM_OC_InitTypeDef sConfigOC = {0};

  htim5.Instance = TIM5;
  htim5.Init.Prescaler = 0;
  htim5.Init.CounterMode = TIM_COUNTERMODE_UP;
  htim5.Init.Period = 4294967295;
  htim5.Init.ClockDivision = TIM_CLOCKDIVISION_DIV1;
  htim5.Init.AutoReloadPreload = TIM_AUTORELOAD_PRELOAD_DISABLE;
  if (HAL_TIM_OC_Init(&htim5) != HAL_OK)
  {
    Error_Handler();
  }
  sMasterConfig.MasterOutputTrigger = TIM_TRGO_RESET;
  sMasterConfig.MasterSlaveMode = TIM_MASTERSLAVEMODE_DISABLE;
  if (HAL_TIMEx_MasterConfigSynchronization(&htim5, &sMasterConfig) != HAL_OK)
  {
    Error_Handler();
  }
  sConfigOC.OCMode = TIM_OCMODE_TIMING;
  sConfigOC.Pulse = 0;
  sConfigOC.OCPolarity = TIM_OCPOLARITY_HIGH;
  sConfigOC.OCFastMode = TIM_OCFAST_DISABLE;
  if (HAL_TIM_OC_ConfigChannel(&htim5, &sConfigOC, TIM_CHANNEL_1) != HAL_OK)
  {
    Error_Handler();
  }

}

static void MX_TIM8_Init(void)
{

  TIM_MasterConfigTypeDef sMasterConfig = {0};
  TIM_IC_InitTypeDef sConfigIC = {0};

  htim8.Instance = TIM8;
  htim8.Init.Prescaler = 0;
  htim8.Init.CounterMode = TIM_COUNTERMODE_UP;
  htim8.Init.Period = 65535;
  htim8.Init.ClockDivision = TIM_CLOCKDIVISION_DIV1;
  htim8.Init.RepetitionCounter = 0;
  htim8.Init.AutoReloadPreload = TIM_AUTORELOAD_PRELOAD_DISABLE;
  if (HAL_TIM_IC_Init(&htim8) != HAL_OK)
  {
    Error_Handler();
  }
  sMasterConfig.MasterOutputTrigger = TIM_TRGO_RESET;
  sMasterConfig.MasterSlaveMode = TIM_MASTERSLAVEMODE_DISABLE;
  if (HAL_TIMEx_MasterConfigSynchronization(&htim8, &sMasterConfig) != HAL_OK)
  {
    Error_Handler();
  }
  sConfigIC.ICPolarity = TIM_INPUTCHANNELPOLARITY_RISING;
  sConfigIC.ICSelection = TIM_ICSELECTION_DIRECTTI;
  sConfigIC.ICPrescaler = TIM_ICPSC_DIV1;
  sConfigIC.ICFilter = 0;
  if (HAL_TIM_IC_ConfigChannel(&htim8, &sConfigIC, TIM_CHANNEL_1) != HAL_OK)
  {
    Error_Handler();
  }
  if (HAL_TIM_IC_ConfigChannel(&htim8, &sConfigIC, TIM_CHANNEL_2) != HAL_OK)
  {
    Error_Handler();
  }

}

static void MX_USART2_UART_Init(void)
{

  huart2.Instance = USART2;
  huart2.Init.BaudRate = 115200;
  huart2.Init.WordLength = UART_WORDLENGTH_8B;
  huart2.Init.StopBits = UART_STOPBITS_1;
  huart2.Init.Parity = UART_PARITY_NONE;
  huart2.Init.Mode = UART_MODE_TX_RX;
  huart2.Init.HwFlowCtl = UART_HWCONTROL_NONE;
  huart2.Init.OverSampling = UART_OVERSAMPLING_16;
  if (HAL_UART_Init(&huart2) != HAL_OK)
  {
    Error_Handler();
  }

}

static void MX_USART3_UART_Init(void)
{

  huart3.Instance = USART3;
  huart3.Init.BaudRate = 115200;
  huart3.Init.WordLength = UART_WORDLENGTH_8B;
  huart3.Init.StopBits = UART_STOPBITS_1;
  huart3.Init.Parity = UART_PARITY_NONE;
  huart3.Init.Mode = UART_MODE_TX_RX;
  huart3.Init.HwFlowCtl = UART_HWCONTROL_NONE;
  huart3.Init.OverSampling = UART_OVERSAMPLING_16;
  if (HAL_UART_Init(&huart3) != HAL_OK)
  {
    Error_Handler();
  }

}

static void MX_USART6_UART_Init(void)
{

  huart6.Instance = USART6;
  huart6.Init.BaudRate = 115200;
  huart6.Init.WordLength = UART_WORDLENGTH_8B;
  huart6.Init.StopBits = UART_STOPBITS_1;
  huart6.Init.Parity = UART_PARITY_NONE;
  huart6.Init.Mode = UART_MODE_TX_RX;
  huart6.Init.HwFlowCtl = UART_HWCONTROL_NONE;
  huart6.Init.OverSampling = UART_OVERSAMPLING_16;
  if (HAL_UART_Init(&huart6) != HAL_OK)
  {
    Error_Handler();
  }

}

static void MX_DMA_Init(void)
{

  /* DMA controller clock enable */
  __HAL_RCC_DMA1_CLK_ENABLE();
  __HAL_RCC_DMA2_CLK_ENABLE();

  /* Configure DMA request hdma_memtomem_dma2_stream3 on DMA2_Stream3 */
  hdma_memtomem_dma2_stream3.Instance = DMA2_Stream3;
  hdma_memtomem_dma2_stream3.Init.Channel = DMA_CHANNEL_0;
  hdma_memtomem_dma2_stream3.Init.Direction = DMA_MEMORY_TO_MEMORY;
  hdma_memtomem_dma2_stream3.Init.PeriphInc = DMA_PINC_ENABLE;
  hdma_memtomem_dma2_stream3.Init.MemInc = DMA_MINC_ENABLE;
  hdma_memtomem_dma2_stream3.Init.PeriphDataAlignment = DMA_PDATAALIGN_BYTE;
  hdma_memtomem_dma2_stream3.Init.MemDataAlignment = DMA_MDATAALIGN_BYTE;
  hdma_memtomem_dma2_stream3.Init.Mode = DMA_NORMAL;
  hdma_memtomem_dma2_stream3.Init.Priority = DMA_PRIORITY_LOW;
  hdma_memtomem_dma2_stream3.Init.FIFOMode = DMA_FIFOMODE_ENABLE;
  hdma_memtomem_dma2_stream3.Init.FIFOThreshold = DMA_FIFO_THRESHOLD_FULL;
  hdma_memtomem_dma2_stream3.Init.MemBurst = DMA_MBURST_SINGLE;
  hdma_memtomem_dma2_stream3.Init.PeriphBurst = DMA_PBURST_SINGLE;
  if (HAL_DMA_Init(&hdma_memtomem_dma2_stream3) != HAL_OK)
  {
    Error_Handler( );
  }

  /* DMA interrupt init */
  /* DMA1_Stream1_IRQn interrupt configuration */
  HAL_NVIC_SetPriority(DMA1_Stream1_IRQn, 5, 0);
  HAL_NVIC_EnableIRQ(DMA1_Stream1_IRQn);
  /* DMA1_Stream3_IRQn interrupt configuration */
  HAL_NVIC_SetPriority(DMA1_Stream3_IRQn, 5, 0);
  HAL_NVIC_EnableIRQ(DMA1_Stream3_IRQn);
  /* DMA1_Stream5_IRQn interrupt configuration */
  HAL_NVIC_SetPriority(DMA1_Stream5_IRQn, 5, 0);
  HAL_NVIC_EnableIRQ(DMA1_Stream5_IRQn);
  /* DMA1_Stream6_IRQn interrupt configuration */
  HAL_NVIC_SetPriority(DMA1_Stream6_IRQn, 5, 0);
  HAL_NVIC_EnableIRQ(DMA1_Stream6_IRQn);
  /* DMA1_Stream7_IRQn interrupt configuration */
  HAL_NVIC_SetPriority(DMA1_Stream7_IRQn, 5, 0);
  HAL_NVIC_EnableIRQ(DMA1_Stream7_IRQn);
  /* DMA2_Stream0_IRQn interrupt configuration */
  HAL_NVIC_SetPriority(DMA2_Stream0_IRQn, 5, 0);
  HAL_NVIC_EnableIRQ(DMA2_Stream0_IRQn);
  /* DMA2_Stream1_IRQn interrupt configuration */
  HAL_NVIC_SetPriority(DMA2_Stream1_IRQn, 5, 0);
  HAL_NVIC_EnableIRQ(DMA2_Stream1_IRQn);
  /* DMA2_Stream2_IRQn interrupt configuration */
  HAL_NVIC_SetPriority(DMA2_Stream2_IRQn, 5, 0);
  HAL_NVIC_EnableIRQ(DMA2_Stream2_IRQn);
  /* DMA2_Stream3_IRQn interrupt configuration */
  HAL_NVIC_SetPriority(DMA2_Stream3_IRQn, 5, 0);
  HAL_NVIC_EnableIRQ(DMA2_Stream3_IRQn);
  /* DMA2_Stream6_IRQn interrupt configuration */
  HAL_NVIC_SetPriority(DMA2_Stream6_IRQn, 5, 0);
  HAL_NVIC_EnableIRQ(DMA2_Stream6_IRQn);

}

static void MX_GPIO_Init(void)
{
  GPIO_InitTypeDef GPIO_InitStruct = {0};

  /* GPIO Ports Clock Enable */
  __HAL_RCC_GPIOE_CLK_ENABLE();
  __HAL_RCC_GPIOC_CLK_ENABLE();
  __HAL_RCC_GPIOF_CLK_ENABLE();
  __HAL_RCC_GPIOH_CLK_ENABLE();
  __HAL_RCC_GPIOA_CLK_ENABLE();
  __HAL_RCC_GPIOB_CLK_ENABLE();
  __HAL_RCC_GPIOG_CLK_ENABLE();
  __HAL_RCC_GPIOD_CLK_ENABLE();

  /*Configure GPIO pin Output Level */
  HAL_GPIO_WritePin(GPIOE, SPI_IO1_Pin|SPI_IO2_Pin, GPIO_PIN_RESET);

  /*Configure GPIO pin Output Level */
  HAL_GPIO_WritePin(PWR_EXT_ENABLE_GPIO_Port, PWR_EXT_ENABLE_Pin, GPIO_PIN_RESET);

  /*Configure GPIO pin Output Level */
  HAL_GPIO_WritePin(GPIOG, DEBUG_LED_BLUE_Pin|DEBUG_LED_GREEN_Pin|DEBUG_LED_RED_Pin, GPIO_PIN_RESET);

  /*Configure GPIO pins : I2C1_GPIO3_Pin I2C1_GPIO5_Pin I2C1_GPIO7_Pin I2C1_GPIO1_Pin */
  GPIO_InitStruct.Pin = I2C1_GPIO3_Pin|I2C1_GPIO5_Pin|I2C1_GPIO7_Pin|I2C1_GPIO1_Pin;
  GPIO_InitStruct.Mode = GPIO_MODE_IT_RISING;
  GPIO_InitStruct.Pull = GPIO_NOPULL;
  HAL_GPIO_Init(GPIOE, &GPIO_InitStruct);

  /*Configure GPIO pins : I2C1_GPIO4_Pin I2C1_GPIO6_Pin PE7 PE8
                           PE9 PE15 I2C1_GPIO2_Pin */
  GPIO_InitStruct.Pin = I2C1_GPIO4_Pin|I2C1_GPIO6_Pin|GPIO_PIN_7|GPIO_PIN_8
                          |GPIO_PIN_9|GPIO_PIN_15|I2C1_GPIO2_Pin;
  GPIO_InitStruct.Mode = GPIO_MODE_ANALOG;
  GPIO_InitStruct.Pull = GPIO_NOPULL;
  HAL_GPIO_Init(GPIOE, &GPIO_InitStruct);

  /*Configure GPIO pins : I2C1_GPIO8_Pin PC14 PC15 I2C2_GPIO6_Pin
                           I2C2_GPIO8_Pin PC3 PC4 PC5
                           TIM8_IO_Pin PC9 UART3_GPIO_Pin */
  GPIO_InitStruct.Pin = I2C1_GPIO8_Pin|GPIO_PIN_14|GPIO_PIN_15|I2C2_GPIO6_Pin
                          |I2C2_GPIO8_Pin|GPIO_PIN_3|GPIO_PIN_4|GPIO_PIN_5
                          |TIM8_IO_Pin|GPIO_PIN_9|UART3_GPIO_Pin;
  GPIO_InitStruct.Mode = GPIO_MODE_ANALOG;
  GPIO_InitStruct.Pull = GPIO_NOPULL;
  HAL_GPIO_Init(GPIOC, &GPIO_InitStruct);

  /*Configure GPIO pins : PF2 PF3 PF4 I2C2_GPIO2_Pin
                           I2C2_GPIO4_Pin PF10 */
  GPIO_InitStruct.Pin = GPIO_PIN_2|GPIO_PIN_3|GPIO_PIN_4|I2C2_GPIO2_Pin
                          |I2C2_GPIO4_Pin|GPIO_PIN_10;
  GPIO_InitStruct.Mode = GPIO_MODE_ANALOG;
  GPIO_InitStruct.Pull = GPIO_NOPULL;
  HAL_GPIO_Init(GPIOF, &GPIO_InitStruct);

  /*Configure GPIO pins : I2C2_GPIO1_Pin I2C2_GPIO3_Pin I2C2_GPIO5_Pin PWR_EXT_FAULT_Pin
                           PWR_STATUS_Pin GPIO1_Pin GPIO2_Pin GPIO3_Pin */
  GPIO_InitStruct.Pin = I2C2_GPIO1_Pin|I2C2_GPIO3_Pin|I2C2_GPIO5_Pin|PWR_EXT_FAULT_Pin
                          |PWR_STATUS_Pin|GPIO1_Pin|GPIO2_Pin|GPIO3_Pin;
  GPIO_InitStruct.Mode = GPIO_MODE_IT_RISING;
  GPIO_InitStruct.Pull = GPIO_NOPULL;
  HAL_GPIO_Init(GPIOF, &GPIO_InitStruct);

  /*Configure GPIO pin : I2C2_GPIO7_Pin */
  GPIO_InitStruct.Pin = I2C2_GPIO7_Pin;
  GPIO_InitStruct.Mode = GPIO_MODE_IT_RISING;
  GPIO_InitStruct.Pull = GPIO_NOPULL;
  HAL_GPIO_Init(I2C2_GPIO7_GPIO_Port, &GPIO_InitStruct);

  /*Configure GPIO pins : PA2 PA3 PA10 PA15 */
  GPIO_InitStruct.Pin = GPIO_PIN_2|GPIO_PIN_3|GPIO_PIN_10|GPIO_PIN_15;
  GPIO_InitStruct.Mode = GPIO_MODE_ANALOG;
  GPIO_InitStruct.Pull = GPIO_NOPULL;
  HAL_GPIO_Init(GPIOA, &GPIO_InitStruct);

  /*Configure GPIO pins : PB0 PB1 PB2 PB10
                           PB11 PB4 PB5 PB6
                           PB7 */
  GPIO_InitStruct.Pin = GPIO_PIN_0|GPIO_PIN_1|GPIO_PIN_2|GPIO_PIN_10
                          |GPIO_PIN_11|GPIO_PIN_4|GPIO_PIN_5|GPIO_PIN_6
                          |GPIO_PIN_7;
  GPIO_InitStruct.Mode = GPIO_MODE_ANALOG;
  GPIO_InitStruct.Pull = GPIO_NOPULL;
  HAL_GPIO_Init(GPIOB, &GPIO_InitStruct);

  /*Configure GPIO pins : PG0 PG1 PG2 PG3
                           PG7 PG8 PG11 PG12
                           PG13 PG15 */
  GPIO_InitStruct.Pin = GPIO_PIN_0|GPIO_PIN_1|GPIO_PIN_2|GPIO_PIN_3
                          |GPIO_PIN_7|GPIO_PIN_8|GPIO_PIN_11|GPIO_PIN_12
                          |GPIO_PIN_13|GPIO_PIN_15;
  GPIO_InitStruct.Mode = GPIO_MODE_ANALOG;
  GPIO_InitStruct.Pull = GPIO_NOPULL;
  HAL_GPIO_Init(GPIOG, &GPIO_InitStruct);

  /*Configure GPIO pins : SPI_IO1_Pin SPI_IO2_Pin */
  GPIO_InitStruct.Pin = SPI_IO1_Pin|SPI_IO2_Pin;
  GPIO_InitStruct.Mode = GPIO_MODE_OUTPUT_PP;
  GPIO_InitStruct.Pull = GPIO_NOPULL;
  GPIO_InitStruct.Speed = GPIO_SPEED_FREQ_LOW;
  HAL_GPIO_Init(GPIOE, &GPIO_InitStruct);

  /*Configure GPIO pin : PWR_EXT_ENABLE_Pin */
  GPIO_InitStruct.Pin = PWR_EXT_ENABLE_Pin;
  GPIO_InitStruct.Mode = GPIO_MODE_OUTPUT_PP;
  GPIO_InitStruct.Pull = GPIO_NOPULL;
  GPIO_InitStruct.Speed = GPIO_SPEED_FREQ_LOW;
  HAL_GPIO_Init(PWR_EXT_ENABLE_GPIO_Port, &GPIO_InitStruct);

  /*Configure GPIO pins : PD8 PD9 TIM2_GPIO_Pin PD11
                           PD2 PD4 PD7 */
  GPIO_InitStruct.Pin = GPIO_PIN_8|GPIO_PIN_9|TIM2_GPIO_Pin|GPIO_PIN_11
                          |GPIO_PIN_2|GPIO_PIN_4|GPIO_PIN_7;
  GPIO_InitStruct.Mode = GPIO_MODE_ANALOG;
  GPIO_InitStruct.Pull = GPIO_NOPULL;
  HAL_GPIO_Init(GPIOD, &GPIO_InitStruct);

  /*Configure GPIO pins : DEBUG_LED_BLUE_Pin DEBUG_LED_GREEN_Pin DEBUG_LED_RED_Pin */
  GPIO_InitStruct.Pin = DEBUG_LED_BLUE_Pin|DEBUG_LED_GREEN_Pin|DEBUG_LED_RED_Pin;
  GPIO_InitStruct.Mode = GPIO_MODE_OUTPUT_PP;
  GPIO_InitStruct.Pull = GPIO_NOPULL;
  GPIO_InitStruct.Speed = GPIO_SPEED_FREQ_LOW;
  HAL_GPIO_Init(GPIOG, &GPIO_InitStruct);

  /*Configure GPIO pin : USER_BUTTON_Pin */
  GPIO_InitStruct.Pin = USER_BUTTON_Pin;
  GPIO_InitStruct.Mode = GPIO_MODE_IT_RISING_FALLING;
  GPIO_InitStruct.Pull = GPIO_NOPULL;
  HAL_GPIO_Init(USER_BUTTON_GPIO_Port, &GPIO_InitStruct);

  /*Configure GPIO pin : UART2_GPIO_Pin */
  GPIO_InitStruct.Pin = UART2_GPIO_Pin;
  GPIO_InitStruct.Mode = GPIO_MODE_IT_RISING;
  GPIO_InitStruct.Pull = GPIO_NOPULL;
  HAL_GPIO_Init(UART2_GPIO_GPIO_Port, &GPIO_InitStruct);

  /*Configure GPIO pin : UART6_GPIO_Pin */
  GPIO_InitStruct.Pin = UART6_GPIO_Pin;
  GPIO_InitStruct.Mode = GPIO_MODE_IT_RISING;
  GPIO_InitStruct.Pull = GPIO_NOPULL;
  HAL_GPIO_Init(UART6_GPIO_GPIO_Port, &GPIO_InitStruct);

  /* EXTI interrupt init*/
  HAL_NVIC_SetPriority(EXTI0_IRQn, 5, 0);
  HAL_NVIC_EnableIRQ(EXTI0_IRQn);

  HAL_NVIC_SetPriority(EXTI1_IRQn, 5, 0);
  HAL_NVIC_EnableIRQ(EXTI1_IRQn);

  HAL_NVIC_SetPriority(EXTI2_IRQn, 5, 0);
  HAL_NVIC_EnableIRQ(EXTI2_IRQn);

  HAL_NVIC_SetPriority(EXTI3_IRQn, 5, 0);
  HAL_NVIC_EnableIRQ(EXTI3_IRQn);

  HAL_NVIC_SetPriority(EXTI4_IRQn, 5, 0);
  HAL_NVIC_EnableIRQ(EXTI4_IRQn);

  HAL_NVIC_SetPriority(EXTI9_5_IRQn, 5, 0);
  HAL_NVIC_EnableIRQ(EXTI9_5_IRQn);

  HAL_NVIC_SetPriority(EXTI15_10_IRQn, 5, 0);
  HAL_NVIC_EnableIRQ(EXTI15_10_IRQn);

}

void StartMainTask(void *argument)
{
  /* init code for USB_DEVICE */
  MX_USB_DEVICE_Init();
  /* USER CODE BEGIN 5 */

  // CAuDri - If enabled, start recording traces used for debugging with Tracealyzer
  #ifdef DEBUG_USE_TRACE_RECORDER
    HAL_GPIO_WritePin(DEBUG_LED_BLUE_GPIO_Port, DEBUG_LED_BLUE_Pin, GPIO_PIN_SET);
    #ifdef DEBUG_WAIT_FOR_TRACEALYZER
      xTraceEnable(TRC_START_AWAIT_HOST);
    #else
      xTraceEnable(TRC_START_FROM_HOST);
    #endif
    // Initialize the logging interface with multiple trace channels
    extern void logger_trace_init();
    logger_trace_init();
    HAL_GPIO_WritePin(DEBUG_LED_BLUE_GPIO_Port, DEBUG_LED_BLUE_Pin, GPIO_PIN_RESET);
  #endif

  osDelay(10);

  // CAuDri - Initialize the thread-safe HAL wrapper
  if (!I2C_Init()) {
      LogError("Main: Failed to initialize thread-safe I2C wrapper");
  }
  if (!CAN_Init()) {
      LogError("Main: Failed to initialize thread-safe CAN wrapper");
  }
  if (ADC_Init() != HAL_OK) {
      LogError("Main: Failed to initialize thread-safe ADC wrapper");
  }

  osDelay(10);

  // CAuDri - Jump to our main entry point in main.cpp
  mainTask();

  /* Infinite loop */
  for(;;)
  {
    osDelay(1);
  }
  /* USER CODE END 5 */
}

void HAL_TIM_PeriodElapsedCallback(TIM_HandleTypeDef *htim)
{
  if (htim->Instance == TIM7)
  {
    HAL_IncTick();
  }
}

void Error_Handler(void)
{
  __disable_irq();
  while (1)
  {
  }
}

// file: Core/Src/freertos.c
/* USER CODE BEGIN Header */
/**
  ******************************************************************************
  * File Name          : freertos.c
  * Description        : Code for freertos applications
  ******************************************************************************
  * @attention
  *
  * Copyright (c) 2025 STMicroelectronics.
  * All rights reserved.
  *
  * This software is licensed under terms that can be found in the LICENSE file
  * in the root directory of this software component.
  * If no LICENSE file comes with this software, it is provided AS-IS.
  *
  ******************************************************************************
  */
/* USER CODE END Header */

#include "FreeRTOS.h"
#include "task.h"
#include "main.h"

/* USER CODE BEGIN Includes */
#include "logger.h"
/* USER CODE END Includes */

/* USER CODE BEGIN PTD */

#define HALT_IF_DEBUGGING()                                 \
  do {                                                      \
    if (CoreDebug->DHCSR & CoreDebug_DHCSR_C_DEBUGEN_Msk) { \
      __asm volatile("bkpt 1");                             \
    }                                                       \
  } while (0)

/* USER CODE END PTD */

/* Hook prototypes */
void configureTimerForRunTimeStats(void);
unsigned long getRunTimeCounterValue(void);
void vApplicationStackOverflowHook(xTaskHandle xTask, signed char *pcTaskName);
void vApplicationMallocFailedHook(void);

/* USER CODE BEGIN 1 */
/* Functions needed when configGENERATE_RUN_TIME_STATS is on */
__weak void configureTimerForRunTimeStats(void)
{

}

__weak unsigned long getRunTimeCounterValue(void)
{
return 0;
}
/* USER CODE END 1 */

/* USER CODE BEGIN 4 */
void vApplicationStackOverflowHook(xTaskHandle xTask, signed char *pcTaskName)
{
    /* Run time stack overflow checking is performed if
    configCHECK_FOR_STACK_OVERFLOW is defined to 1 or 2. This hook function is
    called if a stack overflow is detected. */

    /**
      * CAuDri - Log the stack overflow error and halt the system
      */
    vTaskSuspendAll();

    LogInline(" ");
    LogInline("------ Stack Overflow in Task: %s ------", pcTaskName);
    LogInline(" ");
    LogInline("FreeRTOS: Stack overflow detected in task '%s'.", pcTaskName);
    LogInline("FreeRTOS: Halting system.");
    LogInline(" ");

    // Signalize error state by blinking the red onboard LED
    HAL_GPIO_WritePin(DEBUG_LED_RED_GPIO_Port, DEBUG_LED_RED_Pin, GPIO_PIN_SET);
    HAL_GPIO_WritePin(DEBUG_LED_GREEN_GPIO_Port, DEBUG_LED_GREEN_Pin, GPIO_PIN_RESET);
    HAL_GPIO_WritePin(DEBUG_LED_BLUE_GPIO_Port, DEBUG_LED_BLUE_Pin, GPIO_PIN_SET);

    HALT_IF_DEBUGGING();

    while(1){
        HAL_GPIO_TogglePin(DEBUG_LED_RED_GPIO_Port, DEBUG_LED_RED_Pin);
        HAL_Delay(100);
    };
}
/* USER CODE END 4 */

/* USER CODE BEGIN 5 */
void vApplicationMallocFailedHook(void)
{
    /* vApplicationMallocFailedHook() will only be called if
    configUSE_MALLOC_FAILED_HOOK is set to 1 in FreeRTOSConfig.h. It is a hook
    function that will get called if a call to pvPortMalloc() fails.
    pvPortMalloc() is called internally by the kernel whenever a task, queue,
    timer or semaphore is created. It is also called by various parts of the
    demo application. If heap_1.c or heap_2.c are used, then the size of the
    heap available to pvPortMalloc() is defined by configTOTAL_HEAP_SIZE in
    FreeRTOSConfig.h, and the xPortGetFreeHeapSize() API function can be used
    to query the size of free heap space that remains (although it does not
    provide information on how the remaining heap might be fragmented). */

    /**
      * CAuDri - Log the malloc failure
      */
    vTaskSuspendAll();

    LogInline(" ");
    LogInline("------ Memory Allocation Failed ------");
    LogInline(" ");
    LogInline("FreeRTOS: Memory allocation failed in pvPortMalloc(), possibly out of heap memory.");
    LogInline("FreeRTOS: Halting system.");
    LogInline(" ");

    extern void vPortGetHeapStats( HeapStats_t *pxHeapStats );
    HeapStats_t xHeapStats;

    vPortGetHeapStats( &xHeapStats );

    LogInline("FreeRTOS Heap Statistics:");
    LogInline("Total heap size: %d", configTOTAL_HEAP_SIZE);
    LogInline("Available heap space: %d", xHeapStats.xAvailableHeapSpaceInBytes);
    LogInline("Largest free block: %d", xHeapStats.xSizeOfLargestFreeBlockInBytes);
    LogInline("Smallest free block: %d", xHeapStats.xSizeOfSmallestFreeBlockInBytes);
    LogInline("Number of free blocks: %d", xHeapStats.xNumberOfFreeBlocks);
    LogInline("Minimum ever free bytes remaining: %d", xHeapStats.xMinimumEverFreeBytesRemaining);
    LogInline("Number of successful allocations: %d", xHeapStats.xNumberOfSuccessfulAllocations);
    LogInline("Number of successful frees: %d", xHeapStats.xNumberOfSuccessfulFrees);

    vTaskSuspendAll();

    // Signalize error state by blinking the blue onboard LED
    HAL_GPIO_WritePin(DEBUG_LED_RED_GPIO_Port, DEBUG_LED_RED_Pin, GPIO_PIN_SET);
    HAL_GPIO_WritePin(DEBUG_LED_GREEN_GPIO_Port, DEBUG_LED_GREEN_Pin, GPIO_PIN_SET);
    HAL_GPIO_WritePin(DEBUG_LED_BLUE_GPIO_Port, DEBUG_LED_BLUE_Pin, GPIO_PIN_RESET);

    HALT_IF_DEBUGGING();

    while(1){
        HAL_GPIO_TogglePin(DEBUG_LED_BLUE_GPIO_Port, DEBUG_LED_BLUE_Pin);
        HAL_Delay(100);
    };
}
/* USER CODE END 5 */
